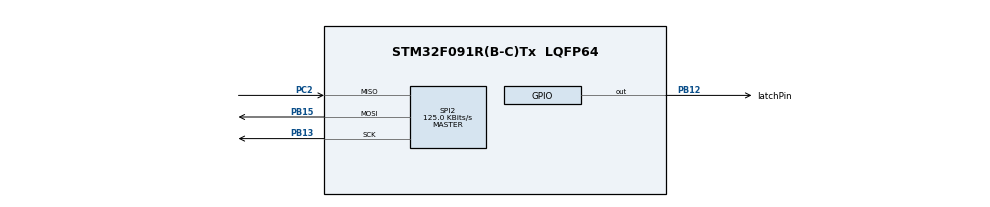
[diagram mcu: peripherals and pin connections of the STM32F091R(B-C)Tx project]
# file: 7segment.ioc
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Mcu.Family=STM32F0
Mcu.Name=STM32F091R(B-C)Tx
Mcu.Package=LQFP64
PB12.GPIO_Label=latchPin
PB12.Signal=GPIO_Output
PB13.Mode=Full_Duplex_Master
PB13.Signal=SPI2_SCK
PB15.Mode=Full_Duplex_Master
PB15.Signal=SPI2_MOSI
PC2.Mode=Full_Duplex_Master
PC2.Signal=SPI2_MISO
PF0-OSC_IN.Mode=HSE-External-Oscillator
PF0-OSC_IN.Signal=RCC_OSC_IN
PF1-OSC_OUT.Mode=HSE-External-Oscillator
PF1-OSC_OUT.Signal=RCC_OSC_OUT
ProjectManager.HeapSize=0x200
ProjectManager.StackSize=0x400
ProjectManager.TargetToolchain=STM32CubeIDE
SPI2.BaudRatePrescaler=SPI_BAUDRATEPRESCALER_64
SPI2.CalculateBaudRate=125.0 KBits/s
SPI2.DataSize=SPI_DATASIZE_8BIT
SPI2.Direction=SPI_DIRECTION_2LINES
SPI2.Mode=SPI_MODE_MASTER
SPI2.NSSPMode=SPI_NSS_PULSE_DISABLE
SPI2.VirtualType=VM_MASTER
TIM2.Period=4800
TIM2.Prescaler=1000
VP_TIM2_VS_ClockSourceINT.Mode=Internal
board=custom

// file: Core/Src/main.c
/* USER CODE BEGIN Header */
/**
  ******************************************************************************
  * @file           : main.c
  * @brief          : Main program body
  ******************************************************************************
  * @attention
  *
  * Copyright (c) 2023 STMicroelectronics.
  * All rights reserved.
  *
  * This software is licensed under terms that can be found in the LICENSE file
  * in the root directory of this software component.
  * If no LICENSE file comes with this software, it is provided AS-IS.
  *
  ******************************************************************************
  */
/* USER CODE END Header */
#include "main.h"
uint8_t segmentSelect = 0x7F;
uint8_t displaySelect = 0x01;
const int latchPin = ((uint16_t)0x1000U);   // pb12 nss
const int clockPin = ((uint16_t)0x2000U);   // pb13 sck
const int dataPin = ((uint16_t)0x8000U);    // pb15 mosi

SPI_HandleTypeDef hspi2;
TIM_HandleTypeDef htim2;

void SystemClock_Config(void);
static void MX_GPIO_Init(void);
static void MX_SPI2_Init(void);
static void MX_TIM2_Init(void);

int main(void)
{

  /* MCU Configuration--------------------------------------------------------*/

  /* Reset of all peripherals, Initializes the Flash interface and the Systick. */
  HAL_Init();

  /* Configure the system clock */
  SystemClock_Config();

  /* Initialize all configured peripherals */
  MX_GPIO_Init();
  MX_SPI2_Init();
  MX_TIM2_Init();
  /* USER CODE BEGIN 2 */
  HAL_TIM_Base_Start_IT(&htim2);	//start timer 2
  HAL_GPIO_WritePin(GPIOB, latchPin, GPIO_PIN_SET);	//set initial state of latch pin as high
  segmentSelect = 0x00;
  displaySelect = 0x01;
  /* USER CODE END 2 */

  /* Infinite loop */
  while (1)
  {

  }
}

void SystemClock_Config(void)
{
  RCC_OscInitTypeDef RCC_OscInitStruct = {0};
  RCC_ClkInitTypeDef RCC_ClkInitStruct = {0};

  /** Initializes the RCC Oscillators according to the specified parameters
  * in the RCC_OscInitTypeDef structure.
  */
  RCC_OscInitStruct.OscillatorType = RCC_OSCILLATORTYPE_HSI;
  RCC_OscInitStruct.HSIState = RCC_HSI_ON;
  RCC_OscInitStruct.HSICalibrationValue = RCC_HSICALIBRATION_DEFAULT;
  RCC_OscInitStruct.PLL.PLLState = RCC_PLL_NONE;
  if (HAL_RCC_OscConfig(&RCC_OscInitStruct) != HAL_OK)
  {
    Error_Handler();
  }

  /** Initializes the CPU, AHB and APB buses clocks
  */
  RCC_ClkInitStruct.ClockType = RCC_CLOCKTYPE_HCLK|RCC_CLOCKTYPE_SYSCLK
                              |RCC_CLOCKTYPE_PCLK1;
  RCC_ClkInitStruct.SYSCLKSource = RCC_SYSCLKSOURCE_HSI;
  RCC_ClkInitStruct.AHBCLKDivider = RCC_SYSCLK_DIV1;
  RCC_ClkInitStruct.APB1CLKDivider = RCC_HCLK_DIV1;

  if (HAL_RCC_ClockConfig(&RCC_ClkInitStruct, FLASH_LATENCY_0) != HAL_OK)
  {
    Error_Handler();
  }
}

static void MX_SPI2_Init(void)
{

  /* SPI2 parameter configuration*/
  hspi2.Instance = SPI2;
  hspi2.Init.Mode = SPI_MODE_MASTER;
  hspi2.Init.Direction = SPI_DIRECTION_2LINES;
  hspi2.Init.DataSize = SPI_DATASIZE_8BIT;
  hspi2.Init.CLKPolarity = SPI_POLARITY_LOW;
  hspi2.Init.CLKPhase = SPI_PHASE_1EDGE;
  hspi2.Init.NSS = SPI_NSS_SOFT;
  hspi2.Init.BaudRatePrescaler = SPI_BAUDRATEPRESCALER_64;
  hspi2.Init.FirstBit = SPI_FIRSTBIT_MSB;
  hspi2.Init.TIMode = SPI_TIMODE_DISABLE;
  hspi2.Init.CRCCalculation = SPI_CRCCALCULATION_DISABLE;
  hspi2.Init.CRCPolynomial = 7;
  hspi2.Init.CRCLength = SPI_CRC_LENGTH_DATASIZE;
  hspi2.Init.NSSPMode = SPI_NSS_PULSE_DISABLE;
  if (HAL_SPI_Init(&hspi2) != HAL_OK)
  {
    Error_Handler();
  }

}

static void MX_TIM2_Init(void)
{

  TIM_ClockConfigTypeDef sClockSourceConfig = {0};
  TIM_MasterConfigTypeDef sMasterConfig = {0};

  htim2.Instance = TIM2;
  htim2.Init.Prescaler = 1000;
  htim2.Init.CounterMode = TIM_COUNTERMODE_UP;
  htim2.Init.Period = 4800;
  htim2.Init.ClockDivision = TIM_CLOCKDIVISION_DIV1;
  htim2.Init.AutoReloadPreload = TIM_AUTORELOAD_PRELOAD_ENABLE;
  if (HAL_TIM_Base_Init(&htim2) != HAL_OK)
  {
    Error_Handler();
  }
  sClockSourceConfig.ClockSource = TIM_CLOCKSOURCE_INTERNAL;
  if (HAL_TIM_ConfigClockSource(&htim2, &sClockSourceConfig) != HAL_OK)
  {
    Error_Handler();
  }
  sMasterConfig.MasterOutputTrigger = TIM_TRGO_RESET;
  sMasterConfig.MasterSlaveMode = TIM_MASTERSLAVEMODE_DISABLE;
  if (HAL_TIMEx_MasterConfigSynchronization(&htim2, &sMasterConfig) != HAL_OK)
  {
    Error_Handler();
  }

}

static void MX_GPIO_Init(void)
{
  GPIO_InitTypeDef GPIO_InitStruct = {0};

  /* GPIO Ports Clock Enable */
  __HAL_RCC_GPIOF_CLK_ENABLE();
  __HAL_RCC_GPIOC_CLK_ENABLE();
  __HAL_RCC_GPIOB_CLK_ENABLE();

  /*Configure GPIO pin Output Level */
  HAL_GPIO_WritePin(latchPin_GPIO_Port, latchPin_Pin, GPIO_PIN_RESET);

  /*Configure GPIO pin : latchPin_Pin */
  GPIO_InitStruct.Pin = latchPin_Pin;
  GPIO_InitStruct.Mode = GPIO_MODE_OUTPUT_PP;
  GPIO_InitStruct.Pull = GPIO_NOPULL;
  GPIO_InitStruct.Speed = GPIO_SPEED_FREQ_LOW;
  HAL_GPIO_Init(latchPin_GPIO_Port, &GPIO_InitStruct);

}

/* USER CODE BEGIN 4 */
void HAL_TIM_PeriodElapsedCallback(TIM_HandleTypeDef* htim)
{
	  // Say something
	  HAL_GPIO_WritePin(GPIOB, latchPin, GPIO_PIN_RESET);	// pull latch pin LOW to send data
	  HAL_SPI_Transmit(&hspi2, (uint8_t *)&segmentSelect, 1, 100);	  // write segment select
	  HAL_SPI_Transmit(&hspi2, (uint8_t *)&displaySelect, 1, 100);	  // write display select
	  HAL_GPIO_WritePin(GPIOB, latchPin, GPIO_PIN_SET); //pull latch pin HIGH to update outputs

	  displaySelect = displaySelect << 1;
	  if(displaySelect == 0x00)
	  {
		  displaySelect = 0x01;
	  }
}
/* USER CODE END 4 */

void Error_Handler(void)
{
  __disable_irq();
  while (1)
  {
  }
}
